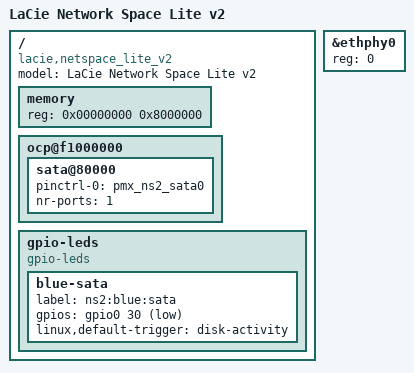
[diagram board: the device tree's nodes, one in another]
// SPDX-License-Identifier: GPL-2.0
/dts-v1/;

#include "kirkwood-ns2-common.dtsi"

/ {
	model = "LaCie Network Space Lite v2";
	compatible = "lacie,netspace_lite_v2", "marvell,kirkwood-88f6192", "marvell,kirkwood";

	memory {
		device_type = "memory";
		reg = <0x00000000 0x8000000>;
	};

	ocp@f1000000 {
		sata@80000 {
			pinctrl-0 = <&pmx_ns2_sata0>;
			pinctrl-names = "default";
			status = "okay";
			nr-ports = <1>;
		};
	};

	gpio-leds {
		compatible = "gpio-leds";

		blue-sata {
			label = "ns2:blue:sata";
			gpios = <&gpio0 30 GPIO_ACTIVE_LOW>;
			linux,default-trigger = "disk-activity";
		};
	};
};

&ethphy0 { reg = <0>; };
